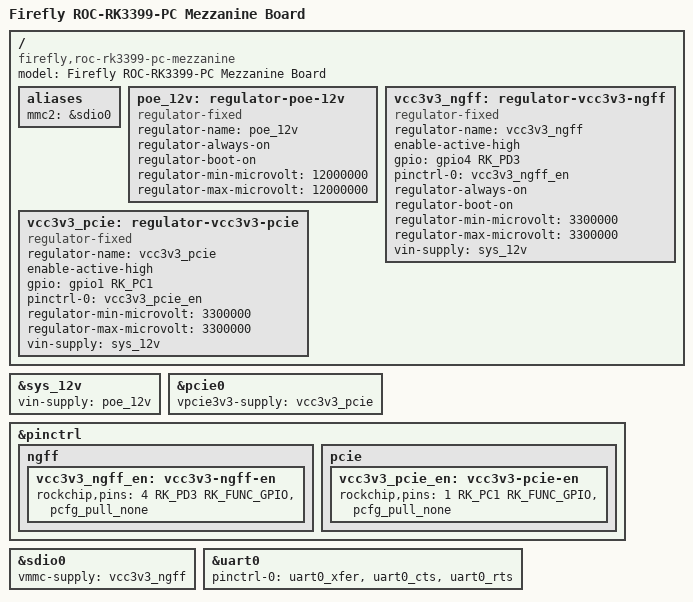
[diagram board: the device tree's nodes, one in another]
// SPDX-License-Identifier: (GPL-2.0+ OR MIT)
/*
 * Copyright (c) 2017 T-Chip Intelligent Technology Co., Ltd
 * Copyright (c) 2019 Markus Reichl <m.reichl@fivetechno.de>
 */

/dts-v1/;
#include "rk3399-roc-pc.dtsi"

/ {
	model = "Firefly ROC-RK3399-PC Mezzanine Board";
	compatible = "firefly,roc-rk3399-pc-mezzanine", "rockchip,rk3399";

	aliases {
		mmc2 = &sdio0;
	};

	/* MP8009 PoE PD */
	poe_12v: regulator-poe-12v {
		compatible = "regulator-fixed";
		regulator-name = "poe_12v";
		regulator-always-on;
		regulator-boot-on;
		regulator-min-microvolt = <12000000>;
		regulator-max-microvolt = <12000000>;
	};

	vcc3v3_ngff: regulator-vcc3v3-ngff {
		compatible = "regulator-fixed";
		regulator-name = "vcc3v3_ngff";
		enable-active-high;
		gpio = <&gpio4 RK_PD3 GPIO_ACTIVE_HIGH>;
		pinctrl-names = "default";
		pinctrl-0 = <&vcc3v3_ngff_en>;
		regulator-always-on;
		regulator-boot-on;
		regulator-min-microvolt = <3300000>;
		regulator-max-microvolt = <3300000>;
		vin-supply = <&sys_12v>;
	};

	vcc3v3_pcie: regulator-vcc3v3-pcie {
		compatible = "regulator-fixed";
		regulator-name = "vcc3v3_pcie";
		enable-active-high;
		gpio = <&gpio1 RK_PC1 GPIO_ACTIVE_HIGH>;
		pinctrl-names = "default";
		pinctrl-0 = <&vcc3v3_pcie_en>;
		regulator-min-microvolt = <3300000>;
		regulator-max-microvolt = <3300000>;
		vin-supply = <&sys_12v>;
	};
};

&sys_12v {
	vin-supply = <&poe_12v>;
};

/*
 * The controller, the four lanes and PERST live on the base board.
 * This file only adds the mezzanine's slot 3.3 V load switch.
 */
&pcie0 {
	vpcie3v3-supply = <&vcc3v3_pcie>;
};

&pinctrl {
	ngff {
		vcc3v3_ngff_en: vcc3v3-ngff-en {
			rockchip,pins = <4 RK_PD3 RK_FUNC_GPIO &pcfg_pull_none>;
		};
	};

	pcie {
		vcc3v3_pcie_en: vcc3v3-pcie-en {
			rockchip,pins = <1 RK_PC1 RK_FUNC_GPIO &pcfg_pull_none>;
		};
	};
};

/*
 * J15 also presents always-on VCC3V3_SYS. The M.2 module is powered
 * from this mezzanine switch instead.
 */
&sdio0 {
	vmmc-supply = <&vcc3v3_ngff>;
};

&uart0 {
	pinctrl-names = "default";
	pinctrl-0 = <&uart0_xfer &uart0_cts &uart0_rts>;
	status = "okay";
};
